# ESP32C5_RADIO register map
Vendor: Espressif; Series: ESP32-C5; File version: 0.1
Registers are 32-bit, read-write, no defined reset value unless marked. A register's access mark holds for its fields unless they carry their own. Offsets are from the block's base; [hi:lo] are bit positions; 'fields as' and 'values as' point back to an identical list.

## MODEM_LPCON_SHARED_CLOCK — ESP32-C5 MODEM_LPCON clock gate at MODEM_BASE + 0xF000 driven by the vendor COEXIST modem clock device, and the power-state map of the analog I2C master clock. Other fields remain absent and are preserved by every field transaction.
Base 0x600AF000
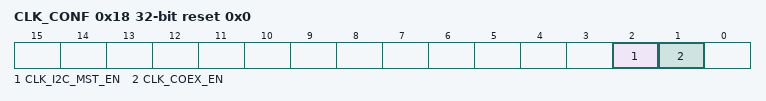
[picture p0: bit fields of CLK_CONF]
0x18 CLK_CONF reset 0x0 — Low-power modem clock gates.
  [2] CLK_I2C_MST_EN — Enable the analog register I2C master clock; the platform keeps its reference count.
  [1] CLK_COEX_EN — Enable the coexistence clock.
0x20 CLK_CONF_POWER_ST reset 0x0 — PMU power states in which each low-power modem clock domain runs.
  [27:24] CLK_I2C_MST_ST_MAP — PMU power states in which the analog register I2C master clock runs, one bit per state (SLEEP, MODEM, ACTIVE). On ESP32-C5 v1.0 the MODEM bit must stay clear: it survives the HP-system reset of a USB Serial/JTAG RTS pulse, after which the ROM boots into UART/SDIO download (docs/hardware-errata.md, ESP32-C5 rev 1.0 USB Serial/JTAG reset erratum).

## I2C_ANA_MST — ESP32-C5 analog register I2C master at MODEM_BASE + 0xF800: the two command hosts, the read-mask word and the host-selection field that the libphy analog-register leaves drive. Other fields remain absent and are preserved by every field transaction.
Base 0x600AF800
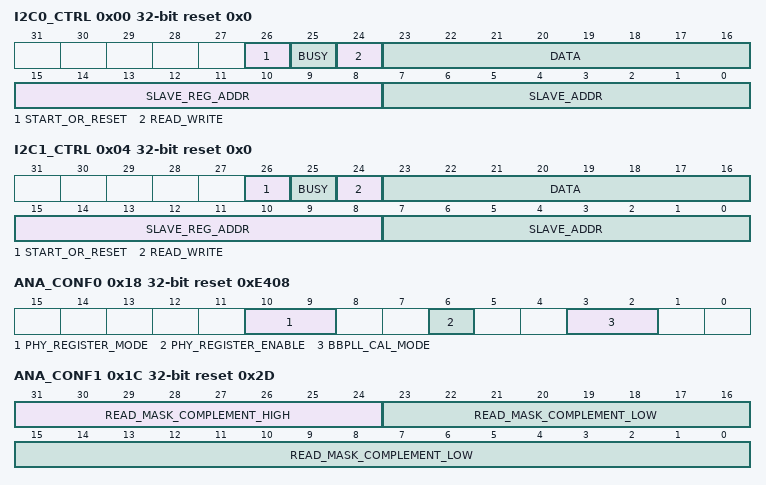
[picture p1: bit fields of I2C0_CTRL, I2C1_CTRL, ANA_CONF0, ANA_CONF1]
0x00 I2C0_CTRL reset 0x0 — Host-0 analog-register command word.
  [26] START_OR_RESET — Project-assigned name. Set by every libphy command publication, above the public 25-bit control field.
  [25] BUSY ro — Project-assigned name. Set while the host executes a command.
  [24] READ_WRITE — Project-assigned name. Set for a write command, clear for a read command.
  [23:16] DATA — Project-assigned name. Byte written, or the byte read once the command completes.
  [15:8] SLAVE_REG_ADDR — Project-assigned name. Register address inside the analog block.
  [7:0] SLAVE_ADDR — Project-assigned name. Analog block code.
0x04 I2C1_CTRL reset 0x0 — Host-1 analog-register command word.
  fields as I2C0_CTRL
0x18 ANA_CONF0 reset 0xE408 — Analog I2C master control used by PHY register mode and BBPLL calibration.
  [10:9] PHY_REGISTER_MODE — Project-assigned name. Two-bit PHY register mode.
  [6] PHY_REGISTER_ENABLE — Project-assigned name. PHY register access enable.
  [3:2] BBPLL_CAL_MODE — Project-assigned name. Two-bit BBPLL calibration mode.
0x1C ANA_CONF1 reset 0x2D — Analog block read-mask word, published complete before every read.
  [31:24] READ_MASK_COMPLEMENT_HIGH — Project-assigned name. High byte of the complemented read mask; the libphy publication sets it to 0xFF.
  [23:0] READ_MASK_COMPLEMENT_LOW — Project-assigned name. Low 24 bits of the complemented one-hot read mask of the block being read.
0x20 ANA_CONF2 reset 0x4 — Analog block host-selection word.
  [16:4] PHY_HOST_MAP — Project-assigned name. Host-selection field that libphy[phy_i2c.o]::phy_get_i2c_hostid_ replaces on every analog-register access while preserving the other bits.
    0x19C1=REVIEWED_RADIO_MAP; 0x206=PARALLEL_INITIALIZATION_MAP
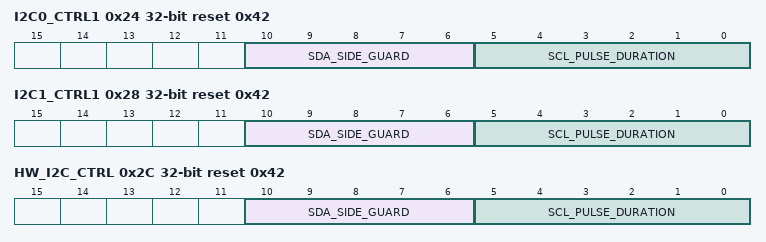
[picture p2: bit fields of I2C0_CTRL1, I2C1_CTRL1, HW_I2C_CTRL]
0x24 I2C0_CTRL1 reset 0x42 — Host-0 bus timing.
  [10:6] SDA_SIDE_GUARD
  [5:0] SCL_PULSE_DURATION — Project-assigned name. SCL pulse duration.
0x28 I2C1_CTRL1 reset 0x42 — Host-1 bus timing.
  fields as I2C0_CTRL1
0x2C HW_I2C_CTRL reset 0x42 — Hardware-host bus timing.
  fields as I2C0_CTRL1

## PMU_RADIO — ESP32-C5 PMU fields that the PHY drives: the analog I2C power and reset controls of the RF blocks and the immediate BB I2C power tie. Other fields remain absent and are preserved by every field transaction.
Base 0x600B0000
0xCC IMM_HP_CK_POWER reset 0x0 — Immediate HP clock and analog power ties.
  [28] TIE_HIGH_XPD_BB_I2C — Tie the BB analog I2C power high; ESP-IDF declares the field write-trigger.
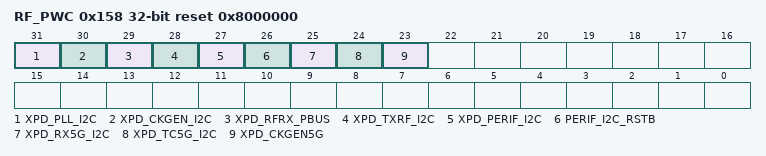
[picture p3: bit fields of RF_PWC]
0x158 RF_PWC reset 0x8000000 — Analog I2C power and reset of the RF blocks.
  [31] XPD_PLL_I2C — Power the analog I2C of the PLL.
  [30] XPD_CKGEN_I2C — Power the analog I2C of the clock generator.
  [29] XPD_RFRX_PBUS — Power the RF receiver PBus.
  [28] XPD_TXRF_I2C — Power the analog I2C of the RF transmitter.
  [27] XPD_PERIF_I2C — Power the peripheral analog I2C.
  [26] PERIF_I2C_RSTB — Release the peripheral analog I2C from reset when set.
  [25] XPD_RX5G_I2C — Power the analog I2C of the 5 GHz receiver.
  [24] XPD_TC5G_I2C — Power the analog I2C of the 5 GHz transceiver.
  [23] XPD_CKGEN5G — Power the 5 GHz clock generator.
